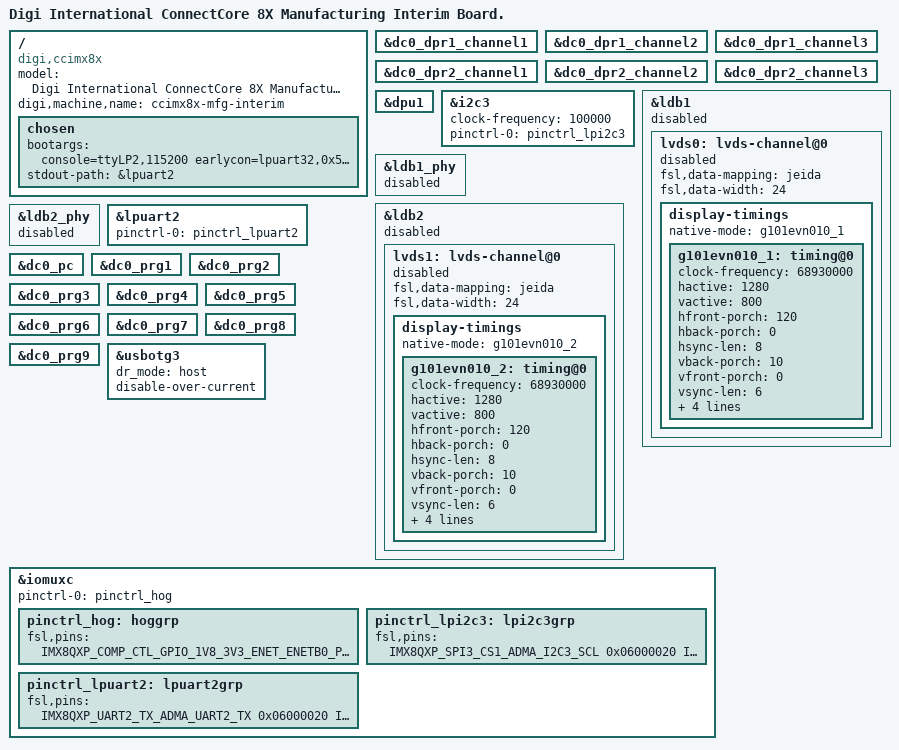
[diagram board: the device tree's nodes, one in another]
/*
 * Copyright 2018-2019, Digi International Inc.
 *
 * Permission to use, copy, modify, and/or distribute this software for any
 * purpose with or without fee is hereby granted, provided that the above
 * copyright notice and this permission notice appear in all copies.
 * THE SOFTWARE IS PROVIDED "AS IS" AND THE AUTHOR DISCLAIMS ALL WARRANTIES
 * WITH REGARD TO THIS SOFTWARE INCLUDING ALL IMPLIED WARRANTIES OF
 * MERCHANTABILITY AND FITNESS. IN NO EVENT SHALL THE AUTHOR BE LIABLE FOR
 * ANY SPECIAL, DIRECT, INDIRECT, OR CONSEQUENTIAL DAMAGES OR ANY DAMAGES
 * WHATSOEVER RESULTING FROM LOSS OF USE, DATA OR PROFITS, WHETHER IN AN
 * ACTION OF CONTRACT, NEGLIGENCE OR OTHER TORTIOUS ACTION, ARISING OUT OF
 * OR IN CONNECTION WITH THE USE OR PERFORMANCE OF THIS SOFTWARE.
 */

/ {
	model = "Digi International ConnectCore 8X Manufacturing Interim Board.";
	compatible = "digi,ccimx8x", "fsl,imx8qxp";
	digi,machine,name = "ccimx8x-mfg-interim";

	chosen {
		bootargs = "console=ttyLP2,115200 earlycon=lpuart32,0x5a080000,115200";
		stdout-path = &lpuart2;
	};
};

&dc0_dpr1_channel1 {
	status = "okay";
};

&dc0_dpr1_channel2 {
	status = "okay";
};

&dc0_dpr1_channel3 {
	status = "okay";
};

&dc0_dpr2_channel1 {
	status = "okay";
};

&dc0_dpr2_channel2 {
	status = "okay";
};

&dc0_dpr2_channel3 {
	status = "okay";
};

&dpu1 {
	status = "okay";
};

&i2c3 {
	#address-cells = <1>;
	#size-cells = <0>;
	clock-frequency = <100000>;
	pinctrl-names = "default";
	pinctrl-0 = <&pinctrl_lpi2c3>;
	status = "okay";
};

&ldb1 {
	pinctrl-names = "default";
	status = "disabled";

	lvds0: lvds-channel@0 {
		fsl,data-mapping = "jeida";
		fsl,data-width = <24>;
		status = "disabled";

		display-timings {
			native-mode = <&g101evn010_1>;

			/* AUO G101EVN01.0 */
			g101evn010_1: timing@0 {
				clock-frequency = <68930000>;
				hactive = <1280>;
				vactive = <800>;
				hfront-porch = <120>;
				hback-porch = <0>;
				hsync-len = <8>;
				vback-porch = <10>;
				vfront-porch = <0>;
				vsync-len = <6>;
				hsync-active = <1>;
				vsync-active = <1>;
				de-active = <1>;
				pixelclk-active = <0>;
			};
		};
	};
};

&ldb1_phy {
	status = "disabled";
};

&ldb2 {
	pinctrl-names = "default";
	status = "disabled";

	lvds1: lvds-channel@0 {
		fsl,data-mapping = "jeida";
		fsl,data-width = <24>;
		status = "disabled";

		display-timings {
			native-mode = <&g101evn010_2>;

			/* AUO G101EVN01.0 */
			g101evn010_2: timing@0 {
				clock-frequency = <68930000>;
				hactive = <1280>;
				vactive = <800>;
				hfront-porch = <120>;
				hback-porch = <0>;
				hsync-len = <8>;
				vback-porch = <10>;
				vfront-porch = <0>;
				vsync-len = <6>;
				hsync-active = <1>;
				vsync-active = <1>;
				de-active = <1>;
				pixelclk-active = <0>;
			};
		};
	};
};

&ldb2_phy {
	status = "disabled";
};

/* Console */
&lpuart2 {
	pinctrl-names = "default";
	pinctrl-0 = <&pinctrl_lpuart2>;
	status = "okay";
};

&dc0_pc {
	status = "okay";
};

&dc0_prg1 {
	status = "okay";
};

&dc0_prg2 {
	status = "okay";
};

&dc0_prg3 {
	status = "okay";
};

&dc0_prg4 {
	status = "okay";
};

&dc0_prg5 {
	status = "okay";
};

&dc0_prg6 {
	status = "okay";
};

&dc0_prg7 {
	status = "okay";
};

&dc0_prg8 {
	status = "okay";
};

&dc0_prg9 {
	status = "okay";
};

&usbotg3 {
	dr_mode = "host";
	disable-over-current;
	status = "okay";
};

/* IOMUX */
&iomuxc {
	pinctrl-names = "default";
	pinctrl-0 = <&pinctrl_hog>;

	pinctrl_hog: hoggrp {
		fsl,pins = <
			/*
			 * The SCFW of B0 defaults ENET0/1 domains to 2.5V:
			 * - VDD_ENET0_1P8_2P5_3P3
			 * - VDD_ENET0_VSELECT_1P8_2P5_3P3
			 * - VDD_ESAI_SPDIF_1P8_2P5_3P3
			 * Turn the domains back to 1.8/3.3V detector
			 */
			IMX8QXP_COMP_CTL_GPIO_1V8_3V3_ENET_ENETB0_PAD	0x000014a0
			IMX8QXP_COMP_CTL_GPIO_1V8_3V3_ENET_ENETB1_PAD	0x000014a0
			IMX8QXP_COMP_CTL_GPIO_1V8_3V3_GPIORHB_PAD		0x000514a0


			/* Castellated pads */
			IMX8QXP_USDHC1_RESET_B_LSIO_GPIO4_IO19		0x06000020
			IMX8QXP_USDHC1_VSELECT_LSIO_GPIO4_IO20		0x06000020
			IMX8QXP_USDHC1_WP_LSIO_GPIO4_IO21		0x06000020
			IMX8QXP_USDHC1_CD_B_LSIO_GPIO4_IO22		0x06000020
			IMX8QXP_USDHC1_CMD_LSIO_GPIO4_IO24		0x06000020
			IMX8QXP_USDHC1_DATA0_LSIO_GPIO4_IO25		0x06000020
			IMX8QXP_USDHC1_DATA1_LSIO_GPIO4_IO26		0x06000020
			IMX8QXP_USDHC1_DATA2_LSIO_GPIO4_IO27		0x06000020
			IMX8QXP_USDHC1_DATA3_LSIO_GPIO4_IO28		0x06000020
			IMX8QXP_USDHC1_CLK_LSIO_GPIO4_IO23			0x06000020
			IMX8QXP_UART0_TX_LSIO_GPIO1_IO22			0x06000020
			IMX8QXP_UART0_RX_LSIO_GPIO1_IO21			0x06000020
			IMX8QXP_MIPI_DSI0_I2C0_SCL_LSIO_GPIO1_IO25		0x06000020
			IMX8QXP_MIPI_DSI0_I2C0_SDA_LSIO_GPIO1_IO26		0x06000020
			IMX8QXP_MIPI_DSI0_GPIO0_00_LSIO_GPIO1_IO27		0x06000020
			IMX8QXP_MIPI_DSI0_GPIO0_01_LSIO_GPIO1_IO28		0x06000020
			IMX8QXP_MIPI_DSI1_I2C0_SCL_LSIO_GPIO1_IO29		0x06000020
			IMX8QXP_MIPI_DSI1_I2C0_SDA_LSIO_GPIO1_IO30		0x06000020
			IMX8QXP_MIPI_DSI1_GPIO0_00_LSIO_GPIO1_IO31		0x06000020
			IMX8QXP_MIPI_DSI1_GPIO0_01_LSIO_GPIO2_IO00		0x06000020
			IMX8QXP_QSPI0A_SS1_B_LSIO_GPIO3_IO15		0x06000020
			IMX8QXP_QSPI0A_SCLK_LSIO_GPIO3_IO16		0x06000020
			IMX8QXP_QSPI0A_DQS_LSIO_GPIO3_IO13			0x06000020
			IMX8QXP_QSPI0A_SS0_B_LSIO_GPIO3_IO14		0x06000020
			IMX8QXP_FLEXCAN2_RX_LSIO_GPIO1_IO19		0x06000020
			IMX8QXP_FLEXCAN2_TX_LSIO_GPIO1_IO20		0x06000020
			IMX8QXP_FLEXCAN1_RX_LSIO_GPIO1_IO17		0x06000020
			IMX8QXP_FLEXCAN1_TX_LSIO_GPIO1_IO18		0x06000020
			IMX8QXP_FLEXCAN0_RX_LSIO_GPIO1_IO15		0x06000020
			IMX8QXP_FLEXCAN0_TX_LSIO_GPIO1_IO16		0x06000020
			IMX8QXP_ADC_IN1_LSIO_GPIO1_IO09			0x06000020
			IMX8QXP_ADC_IN0_LSIO_GPIO1_IO10			0x06000020
			IMX8QXP_MCLK_OUT0_LSIO_GPIO0_IO20			0x06000020
			IMX8QXP_MCLK_IN0_LSIO_GPIO0_IO19			0x06000020
			IMX8QXP_SPI3_SCK_LSIO_GPIO0_IO13			0x06000020
			IMX8QXP_SPI3_SDO_LSIO_GPIO0_IO14			0x06000020
			IMX8QXP_SPI3_SDI_LSIO_GPIO0_IO15			0x06000020
			IMX8QXP_SPI3_CS0_LSIO_GPIO0_IO16			0x06000020
			IMX8QXP_ENET0_RGMII_TXC_LSIO_GPIO4_IO29		0x06000020
			IMX8QXP_ENET0_RGMII_TX_CTL_LSIO_GPIO4_IO30		0x06000020
			IMX8QXP_ENET0_RGMII_TXD0_LSIO_GPIO4_IO31		0x06000020
			IMX8QXP_ENET0_RGMII_TXD1_LSIO_GPIO5_IO00		0x06000020
			IMX8QXP_ENET0_RGMII_TXD2_LSIO_GPIO5_IO01		0x06000020
			IMX8QXP_ENET0_RGMII_TXD3_LSIO_GPIO5_IO02		0x06000020
			IMX8QXP_ENET0_RGMII_RXC_LSIO_GPIO5_IO03		0x06000020
			IMX8QXP_ENET0_RGMII_RX_CTL_LSIO_GPIO5_IO04		0x06000020
			IMX8QXP_ENET0_RGMII_RXD0_LSIO_GPIO5_IO05		0x06000020
			IMX8QXP_ENET0_RGMII_RXD1_LSIO_GPIO5_IO06		0x06000020
			IMX8QXP_ENET0_RGMII_RXD2_LSIO_GPIO5_IO07		0x06000020
			IMX8QXP_ENET0_RGMII_RXD3_LSIO_GPIO5_IO08		0x06000020
			IMX8QXP_ENET0_REFCLK_125M_25M_LSIO_GPIO5_IO09	0x06000020
			IMX8QXP_ENET0_MDIO_LSIO_GPIO5_IO10			0x06000020
			IMX8QXP_ENET0_MDC_LSIO_GPIO5_IO11			0x06000020
			/* LGA pads */
			IMX8QXP_ESAI0_SCKR_LSIO_GPIO0_IO02			0x06000020
			IMX8QXP_ESAI0_SCKT_LSIO_GPIO0_IO03			0x06000020
			IMX8QXP_ESAI0_TX1_LSIO_GPIO0_IO05			0x06000020
			IMX8QXP_USB_SS3_TC1_LSIO_GPIO4_IO04		0x06000020
			IMX8QXP_USB_SS3_TC0_LSIO_GPIO4_IO03		0x06000020
			IMX8QXP_USB_SS3_TC2_LSIO_GPIO4_IO05		0x06000020
			IMX8QXP_USB_SS3_TC3_LSIO_GPIO4_IO06		0x06000020
			IMX8QXP_SPI2_CS0_LSIO_GPIO1_IO00			0x06000020
			IMX8QXP_SPI2_SDI_LSIO_GPIO1_IO02			0x06000020
			IMX8QXP_SAI0_TXFS_LSIO_GPIO0_IO28			0x06000020
			IMX8QXP_ESAI0_TX2_RX3_LSIO_GPIO0_IO06		0x06000020
			IMX8QXP_ESAI0_FST_LSIO_GPIO0_IO01			0x06000020
			IMX8QXP_ESAI0_TX4_RX1_LSIO_GPIO0_IO08		0x06000020
			IMX8QXP_SPDIF0_TX_LSIO_GPIO0_IO11			0x06000020
			IMX8QXP_SPI0_SCK_LSIO_GPIO1_IO04			0x06000020
			IMX8QXP_SPI2_SDO_LSIO_GPIO1_IO01			0x06000020
			IMX8QXP_SAI1_RXD_LSIO_GPIO0_IO29			0x06000020
			IMX8QXP_ESAI0_TX5_RX0_LSIO_GPIO0_IO09		0x06000020
			IMX8QXP_SPDIF0_RX_LSIO_GPIO0_IO10			0x06000020
			IMX8QXP_ESAI0_TX0_LSIO_GPIO0_IO04			0x06000020
			IMX8QXP_ESAI0_TX3_RX2_LSIO_GPIO0_IO07		0x06000020
			IMX8QXP_SPDIF0_EXT_CLK_LSIO_GPIO0_IO12		0x06000020
			IMX8QXP_SPI2_SCK_LSIO_GPIO1_IO03			0x06000020
			IMX8QXP_SPI0_CS0_LSIO_GPIO1_IO08			0x06000020
			IMX8QXP_SPI0_SDO_LSIO_GPIO1_IO06			0x06000020
			IMX8QXP_SAI0_TXD_LSIO_GPIO0_IO25			0x06000020
			IMX8QXP_SAI0_RXD_LSIO_GPIO0_IO27			0x06000020
			IMX8QXP_SPI0_SDI_LSIO_GPIO1_IO05			0x06000020
			IMX8QXP_SAI0_TXC_LSIO_GPIO0_IO26			0x06000020
			IMX8QXP_SAI1_RXC_LSIO_GPIO0_IO30			0x06000020
			IMX8QXP_SAI1_RXFS_LSIO_GPIO0_IO31			0x06000020
			IMX8QXP_SPI0_CS1_LSIO_GPIO1_IO07			0x06000020
			IMX8QXP_QSPI0B_DATA3_LSIO_GPIO3_IO21		0x06000020
			IMX8QXP_QSPI0B_DATA1_LSIO_GPIO3_IO19		0x06000020
			IMX8QXP_QSPI0B_SS1_B_LSIO_GPIO3_IO24		0x06000020
			IMX8QXP_QSPI0B_DATA0_LSIO_GPIO3_IO18		0x06000020
			IMX8QXP_QSPI0B_DQS_LSIO_GPIO3_IO22			0x06000020
			IMX8QXP_QSPI0B_SS0_B_LSIO_GPIO3_IO23		0x06000020
			IMX8QXP_QSPI0B_DATA2_LSIO_GPIO3_IO20		0x06000020
			IMX8QXP_QSPI0B_SCLK_LSIO_GPIO3_IO17		0x06000020
			IMX8QXP_ADC_IN4_LSIO_GPIO1_IO14			0x06000020
			IMX8QXP_ADC_IN3_LSIO_GPIO1_IO11			0x06000020
			IMX8QXP_ADC_IN2_LSIO_GPIO1_IO12			0x06000020
			IMX8QXP_ADC_IN5_LSIO_GPIO1_IO13			0x06000020
			IMX8QXP_CSI_PCLK_LSIO_GPIO3_IO00			0x06000020
			IMX8QXP_CSI_MCLK_LSIO_GPIO3_IO01			0x06000020
			IMX8QXP_MIPI_CSI0_I2C0_SDA_LSIO_GPIO3_IO06		0x06000020
			IMX8QXP_MIPI_CSI0_I2C0_SCL_LSIO_GPIO3_IO05		0x06000020
			IMX8QXP_CSI_RESET_LSIO_GPIO3_IO03			0x06000020
			IMX8QXP_CSI_EN_LSIO_GPIO3_IO02			0x06000020
			IMX8QXP_MIPI_CSI0_MCLK_OUT_LSIO_GPIO3_IO04		0x06000020
			IMX8QXP_SCU_GPIO0_00_LSIO_GPIO2_IO03		0x06000020
		>;
	};

	pinctrl_lpi2c3: lpi2c3grp {
		fsl,pins = <
			IMX8QXP_SPI3_CS1_ADMA_I2C3_SCL	0x06000020
			IMX8QXP_MCLK_IN1_ADMA_I2C3_SDA	0x06000020
		>;
	};

	pinctrl_lpuart2: lpuart2grp {
		fsl,pins = <
			IMX8QXP_UART2_TX_ADMA_UART2_TX	0x06000020
			IMX8QXP_UART2_RX_ADMA_UART2_RX	0x06000020
		>;
	};
};
